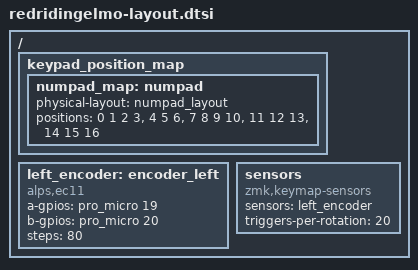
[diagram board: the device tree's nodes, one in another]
/ {
    keypad_position_map {
        // Other properties

        numpad_map: numpad {
            physical-layout = <&numpad_layout>;
            positions
                = < 0  1  2  3>
                , < 4  5  6   >
                , < 7  8 9  10>
                , <11 12 13   >
                , <   14 15 16>;
        };
    };
        left_encoder: encoder_left {
        compatible = "alps,ec11";
        a-gpios = <&pro_micro 19 (GPIO_ACTIVE_HIGH | GPIO_PULL_UP)>;
        b-gpios = <&pro_micro 20 (GPIO_ACTIVE_HIGH | GPIO_PULL_UP)>;
        steps = <80>;
        status = "disabled";
    };

    sensors: sensors {
        compatible = "zmk,keymap-sensors";
        sensors = <&left_encoder>;
        triggers-per-rotation = <20>;
    };
};

&left_encoder {
    status = "okay";
};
